# WKUP_CTRL_MMR0_CFG0 register map
Vendor: Texas Instruments
Registers are 32-bit, read-write, reset 0x0 unless marked. A register's access mark holds for its fields unless they carry their own. Offsets are as the file gives them; [hi:lo] are bit positions; {n}, {i} and the like mark numbered series; 'fields as' and 'values as' point back to an identical list.

## WKUP_CTRL_MMR0_CFG0 (part 3 of 11)
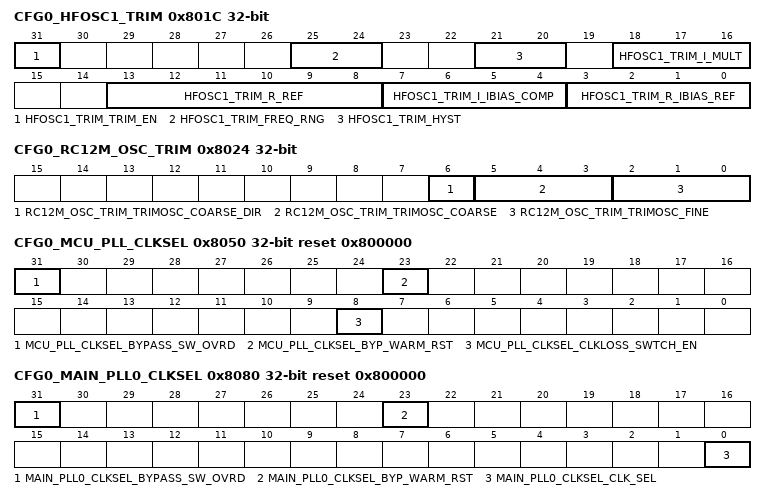
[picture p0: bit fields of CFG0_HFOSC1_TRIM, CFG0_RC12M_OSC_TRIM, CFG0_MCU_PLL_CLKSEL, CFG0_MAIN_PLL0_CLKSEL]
0x801C CFG0_HFOSC1_TRIM — Provides frequency trimming for oscillator 1
  [31] HFOSC1_TRIM_TRIM_EN — Apply MMR values to OSC trim inputs instead of tie-offs
  [25:24] HFOSC1_TRIM_FREQ_RNG — Sets the frequency range of operation based on:I(MIRRBIAS) = I(AGC) + 4x I(BIAS) (I(BIAS) : Bias current to AMP_AGC Block, I(AGC) : Current from AGC Loop and mirrored)
  [21:20] HFOSC1_TRIM_HYST — Sets comparator hysteresis
  [18:16] HFOSC1_TRIM_I_MULT — AGC AMP current multiplication gainI(MIRRBIAS) = I(AGC) + 4x I(BIAS) (I(BIAS) : Bias current to AMP_AGC Block, I(AGC) : Current from AGC Loop and mirrored)
  [13:8] HFOSC1_TRIM_R_REF — Sets the AMP AGC bias currentr_ref(5:3) are not used.
  [7:4] HFOSC1_TRIM_I_IBIAS_COMP — Sets the COMP bias currentx = 1 uA
  [3:0] HFOSC1_TRIM_R_IBIAS_REF — Sets the base IBIAS reference
0x8024 CFG0_RC12M_OSC_TRIM — Provides frequency trimming for the 12.5 MHz RC oscillator module
  [6] RC12M_OSC_TRIM_TRIMOSC_COARSE_DIR — Coarse adjustment direction. If output is greater than 12.5 0 - Coarse adjustment decreases frequency 1 - Coarse adjustment increases frequency
  [5:3] RC12M_OSC_TRIM_TRIMOSC_COARSE — Coarse adjustment. Frequency is decreased or increased by 1.25 MHz per value based on the trimosc_coarse_dir value.
  [2:0] RC12M_OSC_TRIM_TRIMOSC_FINE — Fine adjustment. Decreases the frequency by 250 KHz per value.
0x8050 CFG0_MCU_PLL_CLKSEL reset 0x800000 — Controls the clock source for MCU voltage domain PLL[2:0]
  [31] MCU_PLL_CLKSEL_BYPASS_SW_OVRD — PLL Bypass warm reset software overrideWhen set, enables software control of exit from bypass mode on a mcu_reset_z for MCU PLL[2:0]. This bit must not be set until after the corresponding byp_warm_rst bit has been cleared or the PLL will immediately enter bypass mode.
  [23] MCU_PLL_CLKSEL_BYP_WARM_RST — PLL bypass mode after warm reset.This bit is only valid when bypass_sw_ovrd is set to 1'b1 to enable bypass software override.This bit is set (1'b1) when an MCU warm reset occurs and will keep MCU PLL[2:0] in bypass mode after reset exit until cleared by software. 1'b0 = Exit bypass mode (based on MCU PLL[2:0]_CTRL_bypass_en bit value) 1'b1 = Maintain bypass mode.
  [8] MCU_PLL_CLKSEL_CLKLOSS_SWTCH_EN — When set, enables automatic switching of MCU PLL[2:0] clock source to CLK_12M_RC if HFOSC0 clock loss is detected
0x8060 CFG0_WKUP_PER_CLKSEL — Controls the wakeup peripheral functional clock source. Allows the main oscillator to be used as the functional clock source for the WKUP_USART and WKUP_I2C when PLLs are powered down.
  [0] WKUP_PER_CLKSEL_MCUPLL_BYPASS — Select the main oscillator clock rather than the PLL generated clock as the functional clock (PLL BYPASS mode). 1'b0:WKUP_I2C functional clock is MCU_PLL1_HSDIV3_CLKOUTWKUP_USART functional clock is MCU_PLL1_HSDIV3_CLKOUT or MAIN_PLL_HSDIV5_CLKOUT as selected by WKUP_USART_CLKSEL.clk_sel 1'b1:WKUP_I2C functional clock is HFOSC0_CLKOUTWKUP_USART functional clock is HFOSC0_CLKOUT
0x8064 CFG0_WKUP_USART_CLKSEL — Controls the functional clock source for WKUP_USART0
  [0] WKUP_USART_CLKSEL_CLK_SEL — WKUP_USART0 FCLK selection 1'b0 - MCU_PLL1_HSDIV3_CLKOUT 1'b1 - MAIN_PLL_HSDIV5_CLKOUT
0x8070 CFG0_WKUP_GPIO_CLKSEL — Controls the functional clock source for WKUP_GPIO
  [1:0] WKUP_GPIO_CLKSEL_WAKE_CLK_SEL — WKUP_GPIO clock selection. Must be set to MCU_SYSCLK0/4 whenever WKUP_GPIO VBUS interface is enabled. Other clock source may be selected as a wake up clock for DeepSleep modes after WKUP_GPIO is gated off through LPSC. Field values (Others are reserved): 2'b00 - MCU_SYSCLK0 / 8 2'b01 - MCU_SYSCLK0 / 8 2'b10 - CLK_32K 2'b11 - CLK_12M_RC
0x8080 CFG0_MAIN_PLL0_CLKSEL reset 0x800000 — Controls the clock source for MAIN voltage domain PLL0
  [31] MAIN_PLL0_CLKSEL_BYPASS_SW_OVRD — PLL Bypass warm reset software overrideWhen set, enables software control of exit from bypass mode on a main_reset_z for MAIN PLL0. This bit must not be set until after the corresponding byp_warm_rst bit has been cleared or the PLL will immediately enter bypass mode.
  [23] MAIN_PLL0_CLKSEL_BYP_WARM_RST — PLL bypass mode after warm reset.This bit is only valid when bypass_sw_ovrd is set to 1'b1 to enable bypass software override.This bit is set (1'b1) when a MAIN warm reset occurs and will keep MAIN PLL0 in bypass mode after reset exit until cleared by software. 1'b0 = Exit bypass mode (based on MAIN PLL0_CTRL_bypass_en bit value) 1'b1 = Maintain bypass mode.
  [0] MAIN_PLL0_CLKSEL_CLK_SEL — Selects the clock source for MAIN PLL0 1'b0 - Use HFOSC0_CLKOUT 1'b1 - Use HFOSC1_CLKOUT
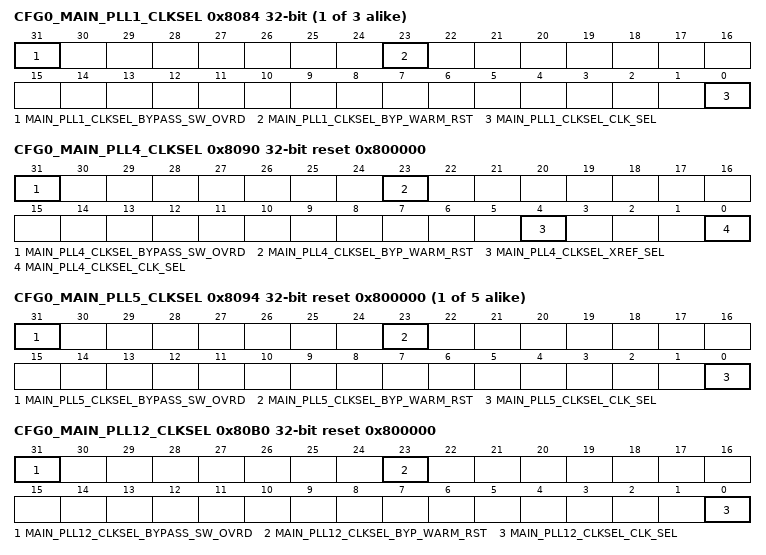
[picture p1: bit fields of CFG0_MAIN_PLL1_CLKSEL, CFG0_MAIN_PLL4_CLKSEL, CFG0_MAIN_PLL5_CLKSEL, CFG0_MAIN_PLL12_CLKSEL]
{0x8080+4i} CFG0_MAIN_PLL{i}_CLKSEL (i=1..3) — Controls the clock source for MAIN voltage domain PLL{i}
  [31] MAIN_PLL{i}_CLKSEL_BYPASS_SW_OVRD — PLL Bypass warm reset software overrideThis bit has no effect on PLL operation as MAIN PLL{i} is reset isolated and exit from bypass mode (in the case of a Thermal reset) is always hardware controlled.
  [23] MAIN_PLL{i}_CLKSEL_BYP_WARM_RST — PLL bypass mode after warm reset.This bit is cleared to 1'b0 when a MAIN warm reset occurs which will cause MAIN PLL{i} to exit bypass mode after reset exit. Setting this bit will have no effect on PLL behavior. Because MAIN PLL{i} is warm reset insensitive, bypass mode will only be entered (and exited) in the case of a Thermal reset event.
  [0] MAIN_PLL{i}_CLKSEL_CLK_SEL — Selects the clock source for MAIN PLL{i} 1'b0 - Use HFOSC0_CLKOUT 1'b1 - Use HFOSC1_CLKOUT
0x8090 CFG0_MAIN_PLL4_CLKSEL reset 0x800000 — Controls the clock source for MAIN voltage domain PLL4
  [31] MAIN_PLL4_CLKSEL_BYPASS_SW_OVRD — PLL Bypass warm reset software overrideWhen set, enables software control of exit from bypass mode on a main_reset_z for MAIN PLL4. This bit must not be set until after the corresponding byp_warm_rst bit has been cleared or the PLL will immediately enter bypass mode.
  [23] MAIN_PLL4_CLKSEL_BYP_WARM_RST — PLL bypass mode after warm reset.This bit is only valid when bypass_sw_ovrd is set to 1'b1 to enable bypass software override.This bit is set (1'b1) when a MAIN warm reset occurs and will keep MAIN PLL4 in bypass mode after reset exit until cleared by software. 1'b0 = Exit bypass mode (based on MAIN PLL4_CTRL_bypass_en bit value) 1'b1 = Maintain bypass mode.
  [4] MAIN_PLL4_CLKSEL_XREF_SEL — Selects the alternate clock source for MAIN PLL4 1'b0 - Use HFOSC0_CLKOUT or HFOSC1 CLKOUT as selected by clk_sel bit 1'b1 - Use EXT_REFCLK1
  [0] MAIN_PLL4_CLKSEL_CLK_SEL — Selects the clock source for MAIN PLL4 1'b0 - Use HFOSC0_CLKOUT 1'b1 - Use HFOSC1_CLKOUT
{0x8080+4i} CFG0_MAIN_PLL{i}_CLKSEL reset 0x800000 (i=5..9) — Controls the clock source for MAIN voltage domain PLL{i}
  [31] MAIN_PLL{i}_CLKSEL_BYPASS_SW_OVRD — PLL Bypass warm reset software overrideWhen set, enables software control of exit from bypass mode on a main_reset_z for MAIN PLL{i}. This bit must not be set until after the corresponding byp_warm_rst bit has been cleared or the PLL will immediately enter bypass mode.
  [23] MAIN_PLL{i}_CLKSEL_BYP_WARM_RST — PLL bypass mode after warm reset.This bit is only valid when bypass_sw_ovrd is set to 1'b1 to enable bypass software override.This bit is set (1'b1) when a MAIN warm reset occurs and will keep MAIN PLL{i} in bypass mode after reset exit until cleared by software. 1'b0 = Exit bypass mode (based on MAIN PLL{i}_CTRL_bypass_en bit value) 1'b1 = Maintain bypass mode.
  [0] MAIN_PLL{i}_CLKSEL_CLK_SEL — Selects the clock source for MAIN PLL{i} 1'b0 - Use HFOSC0_CLKOUT 1'b1 - Use HFOSC1_CLKOUT
0x80B0 CFG0_MAIN_PLL12_CLKSEL reset 0x800000 — Controls the clock source for MAIN voltage domain PLL12
  [31] MAIN_PLL12_CLKSEL_BYPASS_SW_OVRD — PLL Bypass warm reset software overrideWhen set, enables software control of exit from bypass mode on a main_reset_z for MAIN PLL12. This bit must not be set until after the corresponding byp_warm_rst bit has been cleared or the PLL will immediately enter bypass mode.
  [23] MAIN_PLL12_CLKSEL_BYP_WARM_RST — PLL bypass mode after warm reset.This bit is only valid when bypass_sw_ovrd is set to 1'b1 to enable bypass software override.This bit is set (1'b1) when a MAIN warm reset occurs and will keep MAIN PLL12 in bypass mode after reset exit until cleared by software. 1'b0 = Exit bypass mode (based on MAIN PLL12_CTRL_bypass_en bit value) 1'b1 = Maintain bypass mode.
  [0] MAIN_PLL12_CLKSEL_CLK_SEL — Selects the clock source for MAIN PLL12 1'b0 - Use HFOSC0_CLKOUT 1'b1 - Use HFOSC1_CLKOUT
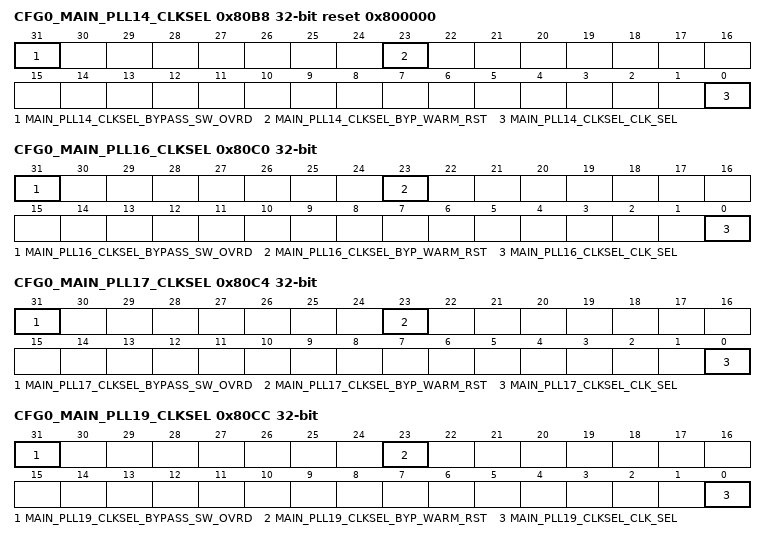
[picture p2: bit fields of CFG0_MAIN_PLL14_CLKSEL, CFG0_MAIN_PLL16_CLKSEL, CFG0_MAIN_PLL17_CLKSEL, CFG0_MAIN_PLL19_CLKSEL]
0x80B8 CFG0_MAIN_PLL14_CLKSEL reset 0x800000 — Controls the clock source for MAIN voltage domain PLL14
  [31] MAIN_PLL14_CLKSEL_BYPASS_SW_OVRD — PLL Bypass warm reset software overrideWhen set, enables software control of exit from bypass mode on a main_reset_z for MAIN PLL14. This bit must not be set until after the corresponding byp_warm_rst bit has been cleared or the PLL will immediately enter bypass mode.
  [23] MAIN_PLL14_CLKSEL_BYP_WARM_RST — PLL bypass mode after warm reset.This bit is only valid when bypass_sw_ovrd is set to 1'b1 to enable bypass software override.This bit is set (1'b1) when a MAIN warm reset occurs and will keep MAIN PLL14 in bypass mode after reset exit until cleared by software. 1'b0 = Exit bypass mode (based on MAIN PLL14_CTRL_bypass_en bit value) 1'b1 = Maintain bypass mode.
  [0] MAIN_PLL14_CLKSEL_CLK_SEL — Selects the clock source for MAIN PLL14 1'b0 - Use HFOSC0_CLKOUT 1'b1 - Use HFOSC1_CLKOUT
0x80C0 CFG0_MAIN_PLL16_CLKSEL — Controls the clock source for MAIN voltage domain PLL16
  [31] MAIN_PLL16_CLKSEL_BYPASS_SW_OVRD — PLL Bypass warm reset software overrideThis bit has no effect on PLL operation as MAIN PLL16 is reset isolated and exit from bypass mode (in the case of a Thermal reset) is always hardware controlled.
  [23] MAIN_PLL16_CLKSEL_BYP_WARM_RST — PLL bypass mode after warm reset.This bit is cleared to 1'b0 when a MAIN warm reset occurs which will cause MAIN PLL16 to exit bypass mode after reset exit. Setting this bit will have no effect on PLL behavior. Because MAIN PLL16 is warm reset insensitive, bypass mode will only be entered (and exited) in the case of a Thermal reset event.
  [0] MAIN_PLL16_CLKSEL_CLK_SEL — Selects the clock source for MAIN PLL16 1'b0 - Use HFOSC0_CLKOUT 1'b1 - Use HFOSC1_CLKOUT
0x80C4 CFG0_MAIN_PLL17_CLKSEL — Controls the clock source for MAIN voltage domain PLL17
  [31] MAIN_PLL17_CLKSEL_BYPASS_SW_OVRD — PLL Bypass warm reset software overrideThis bit has no effect on PLL operation as MAIN PLL17 is reset isolated and exit from bypass mode (in the case of a Thermal reset) is always hardware controlled.
  [23] MAIN_PLL17_CLKSEL_BYP_WARM_RST — PLL bypass mode after warm reset.This bit is cleared to 1'b0 when a MAIN warm reset occurs which will cause MAIN PLL17 to exit bypass mode after reset exit. Setting this bit will have no effect on PLL behavior. Because MAIN PLL17 is warm reset insensitive, bypass mode will only be entered (and exited) in the case of a Thermal reset event.
  [0] MAIN_PLL17_CLKSEL_CLK_SEL — Selects the clock source for MAIN PLL17 1'b0 - Use HFOSC0_CLKOUT 1'b1 - Use HFOSC1_CLKOUT
0x80CC CFG0_MAIN_PLL19_CLKSEL — Controls the clock source for MAIN voltage domain PLL19
  [31] MAIN_PLL19_CLKSEL_BYPASS_SW_OVRD — PLL Bypass warm reset software overrideThis bit has no effect on PLL operation as MAIN PLL19 is reset isolated and exit from bypass mode (in the case of a Thermal reset) is always hardware controlled.
  [23] MAIN_PLL19_CLKSEL_BYP_WARM_RST — PLL bypass mode after warm reset.This bit is cleared to 1'b0 when a MAIN warm reset occurs which will cause MAIN PLL19 to exit bypass mode after reset exit. Setting this bit will have no effect on PLL behavior. Because MAIN PLL19 is warm reset insensitive, bypass mode will only be entered (and exited) in the case of a Thermal reset event.
  [0] MAIN_PLL19_CLKSEL_CLK_SEL — Selects the clock source for MAIN PLL19 1'b0 - Use HFOSC0_CLKOUT 1'b1 - Use HFOSC1_CLKOUT
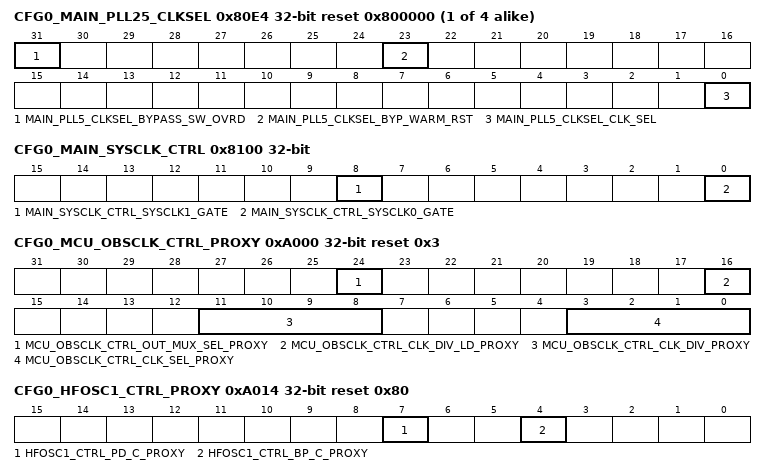
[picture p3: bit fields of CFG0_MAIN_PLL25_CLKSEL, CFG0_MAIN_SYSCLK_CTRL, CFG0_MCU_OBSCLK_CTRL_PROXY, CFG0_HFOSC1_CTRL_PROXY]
{0x8080+4i} CFG0_MAIN_PLL{i}_CLKSEL reset 0x800000 (i=25..28) — Controls the clock source for MAIN voltage domain PLL{i}
  fields as CFG0_MAIN_PLL5_CLKSEL
0x8100 CFG0_MAIN_SYSCLK_CTRL — Controls clock gating of the MAIN PLL Controller SYSCLK outputs
  [8] MAIN_SYSCLK_CTRL_SYSCLK1_GATE — When set, gates off SYSCLK1 output of the MAIN PLL Controller
  [0] MAIN_SYSCLK_CTRL_SYSCLK0_GATE — When set, gates off SYSCLK0 (MCLK1) output of the MAIN PLL Controller
0x8110 CFG0_MCU_SPI0_CLKSEL — MCU_SPI0 clock control
  [16] MCU_SPI0_CLKSEL_MSTR_LB_CLKSEL — Master mode receive capture clock loopback selection 1'b0 - Internal clock loopback 1'b1 - Loopback from pad
0x8114 CFG0_MCU_SPI1_CLKSEL — MCU_SPI1 clock control
  [16] MCU_SPI1_CLKSEL_MSTR_LB_CLKSEL — Master mode receive capture clock loopback selection 1'b0 - Internal clock loopback 1'b1 - Loopback from pad
{0x9100+4i} CFG0_CLAIMREG_P2_R{i}_READONLY ro (i=0..2)
  [31:0] CLAIMREG_P2_R{i}_READONLY — Claim bits for Partition 2
0xA000 CFG0_MCU_OBSCLK_CTRL_PROXY reset 0x3 — Controls which internal clock is made observable on the MCU_OBSCLK output pin
  [24] MCU_OBSCLK_CTRL_OUT_MUX_SEL_PROXY — MCU_OBSCLK pin output mux selection.Note, when HFOSC0_CLK is selected (1'b1) the MCU_OBSCLK_CTRL_clk_sel field must be programmed to 4'b0001. 1'b0 - The output of the MCU_OBSCLK output divider is output on the pin 1'b1 - HFOSC0_CLK is output on the pin
  [16] MCU_OBSCLK_CTRL_CLK_DIV_LD_PROXY — Load the output divider valueWriting 1 to this bit will generate a load pulse to load the OBSCLK divider value. This bit can be cleared but must not be set in the same write cycle in which the clk_div value is changed.
  [11:8] MCU_OBSCLK_CTRL_CLK_DIV_PROXY — MCU_OBSCLK pin clock selection output dividerOutput clock is divided by clk_div+1
  [3:0] MCU_OBSCLK_CTRL_CLK_SEL_PROXY — MCU_OBSCLK pin clock selection Field values (Others are reserved): 4'b0000 - CLK_12M_RC 4'b0001 - 0 4'b0010 - MCU_PLL0_HSDIV0_CLKOUT 4'b0011 - MCU_PLLCTL_OBSCLK 4'b0100 - MCU_PLL1_HSDIV1_CLKOUT 4'b0101 - MCU_PLL1_HSDIV2_CLKOUT 4'b0110 - MCU_PLL1_HSDIV3_CLKOUT 4'b0111 - MCU_PLL1_HSDIV4_CLKOUT 4'b1000 - MCU_PLL2_HSDIV0_CLKOUT 4'b1001 - CLK_32K 4'b1010 - MCU_PLL2_HSDIV1_CLKOUT 4'b1011 - MCU_PLL2_HSDIV2_CLKOUT 4'b1100 - MCU_PLL2_HSDIV3_CLKOUT 4'b1101 - MCU_PLL2_HSDIV4_CLKOUT 4'b1110 - HFOSC0_CLKOUT 4'b1111 - LFXOSC_CLKOUT
0xA014 CFG0_HFOSC1_CTRL_PROXY reset 0x80 — Controls the operation of oscillator 1
  [7] HFOSC1_CTRL_PD_C_PROXY — Oscillator powerdown control. When set, oscillator is disabled. Oscillator output is tristated if bp_c=0
  [4] HFOSC1_CTRL_BP_C_PROXY — Oscillator bypass control. When set oscillator is in bypass mode
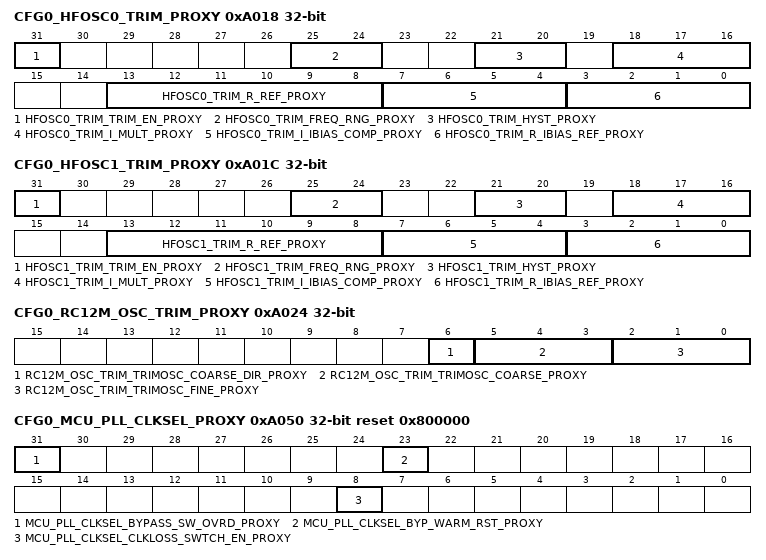
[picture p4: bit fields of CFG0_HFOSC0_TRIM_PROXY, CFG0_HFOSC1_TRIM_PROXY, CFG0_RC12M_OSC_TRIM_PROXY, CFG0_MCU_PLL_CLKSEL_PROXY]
0xA018 CFG0_HFOSC0_TRIM_PROXY — Provides frequency trimming for oscillator 0
  [31] HFOSC0_TRIM_TRIM_EN_PROXY — Apply MMR values to OSC trim inputs instead of tie-offs
  [25:24] HFOSC0_TRIM_FREQ_RNG_PROXY — Sets the frequency range of operation based on:I(MIRRBIAS) = I(AGC) + 4x I(BIAS) (I(BIAS) : Bias current to AMP_AGC Block, I(AGC) : Current from AGC Loop and mirrored)
  [21:20] HFOSC0_TRIM_HYST_PROXY — Sets comparator hysteresis
  [18:16] HFOSC0_TRIM_I_MULT_PROXY — AGC AMP current multiplication gainI(MIRRBIAS) = I(AGC) + 4x I(BIAS) (I(BIAS) : Bias current to AMP_AGC Block, I(AGC) : Current from AGC Loop and mirrored)
  [13:8] HFOSC0_TRIM_R_REF_PROXY — Sets the AMP AGC bias currentr_ref(5:3) are not used.
  [7:4] HFOSC0_TRIM_I_IBIAS_COMP_PROXY — Sets the COMP bias currentx = 1 uA
  [3:0] HFOSC0_TRIM_R_IBIAS_REF_PROXY — Sets the base IBIAS reference
0xA01C CFG0_HFOSC1_TRIM_PROXY — Provides frequency trimming for oscillator 1
  [31] HFOSC1_TRIM_TRIM_EN_PROXY — Apply MMR values to OSC trim inputs instead of tie-offs
  [25:24] HFOSC1_TRIM_FREQ_RNG_PROXY — Sets the frequency range of operation based on:I(MIRRBIAS) = I(AGC) + 4x I(BIAS) (I(BIAS) : Bias current to AMP_AGC Block, I(AGC) : Current from AGC Loop and mirrored)
  [21:20] HFOSC1_TRIM_HYST_PROXY — Sets comparator hysteresis
  [18:16] HFOSC1_TRIM_I_MULT_PROXY — AGC AMP current multiplication gainI(MIRRBIAS) = I(AGC) + 4x I(BIAS) (I(BIAS) : Bias current to AMP_AGC Block, I(AGC) : Current from AGC Loop and mirrored)
  [13:8] HFOSC1_TRIM_R_REF_PROXY — Sets the AMP AGC bias currentr_ref(5:3) are not used.
  [7:4] HFOSC1_TRIM_I_IBIAS_COMP_PROXY — Sets the COMP bias currentx = 1 uA
  [3:0] HFOSC1_TRIM_R_IBIAS_REF_PROXY — Sets the base IBIAS reference
0xA024 CFG0_RC12M_OSC_TRIM_PROXY — Provides frequency trimming for the 12.5 MHz RC oscillator module
  [6] RC12M_OSC_TRIM_TRIMOSC_COARSE_DIR_PROXY — Coarse adjustment direction. If output is greater than 12.5 0 - Coarse adjustment decreases frequency 1 - Coarse adjustment increases frequency
  [5:3] RC12M_OSC_TRIM_TRIMOSC_COARSE_PROXY — Coarse adjustment. Frequency is decreased or increased by 1.25 MHz per value based on the trimosc_coarse_dir value.
  [2:0] RC12M_OSC_TRIM_TRIMOSC_FINE_PROXY — Fine adjustment. Decreases the frequency by 250 KHz per value.
0xA050 CFG0_MCU_PLL_CLKSEL_PROXY reset 0x800000 — Controls the clock source for MCU voltage domain PLL[2:0]
  [31] MCU_PLL_CLKSEL_BYPASS_SW_OVRD_PROXY — PLL Bypass warm reset software overrideWhen set, enables software control of exit from bypass mode on a mcu_reset_z for MCU PLL[2:0]. This bit must not be set until after the corresponding byp_warm_rst bit has been cleared or the PLL will immediately enter bypass mode.
  [23] MCU_PLL_CLKSEL_BYP_WARM_RST_PROXY — PLL bypass mode after warm reset.This bit is only valid when bypass_sw_ovrd is set to 1'b1 to enable bypass software override.This bit is set (1'b1) when an MCU warm reset occurs and will keep MCU PLL[2:0] in bypass mode after reset exit until cleared by software. 1'b0 = Exit bypass mode (based on MCU PLL[2:0]_CTRL_bypass_en bit value) 1'b1 = Maintain bypass mode.
  [8] MCU_PLL_CLKSEL_CLKLOSS_SWTCH_EN_PROXY — When set, enables automatic switching of MCU PLL[2:0] clock source to CLK_12M_RC if HFOSC0 clock loss is detected
0xA060 CFG0_WKUP_PER_CLKSEL_PROXY — Controls the wakeup peripheral functional clock source. Allows the main oscillator to be used as the functional clock source for the WKUP_USART and WKUP_I2C when PLLs are powered down.
  [0] WKUP_PER_CLKSEL_MCUPLL_BYPASS_PROXY — Select the main oscillator clock rather than the PLL generated clock as the functional clock (PLL BYPASS mode). 1'b0:WKUP_I2C functional clock is MCU_PLL1_HSDIV3_CLKOUTWKUP_USART functional clock is MCU_PLL1_HSDIV3_CLKOUT or MAIN_PLL_HSDIV5_CLKOUT as selected by WKUP_USART_CLKSEL.clk_sel 1'b1:WKUP_I2C functional clock is HFOSC0_CLKOUTWKUP_USART functional clock is HFOSC0_CLKOUT
0xA064 CFG0_WKUP_USART_CLKSEL_PROXY — Controls the functional clock source for WKUP_USART0
  [0] WKUP_USART_CLKSEL_CLK_SEL_PROXY — WKUP_USART0 FCLK selection 1'b0 - MCU_PLL1_HSDIV3_CLKOUT 1'b1 - MAIN_PLL_HSDIV5_CLKOUT
0xA070 CFG0_WKUP_GPIO_CLKSEL_PROXY — Controls the functional clock source for WKUP_GPIO
  [1:0] WKUP_GPIO_CLKSEL_WAKE_CLK_SEL_PROXY — WKUP_GPIO clock selection. Must be set to MCU_SYSCLK0/4 whenever WKUP_GPIO VBUS interface is enabled. Other clock source may be selected as a wake up clock for DeepSleep modes after WKUP_GPIO is gated off through LPSC. Field values (Others are reserved): 2'b00 - MCU_SYSCLK0 / 8 2'b01 - MCU_SYSCLK0 / 8 2'b10 - CLK_32K 2'b11 - CLK_12M_RC
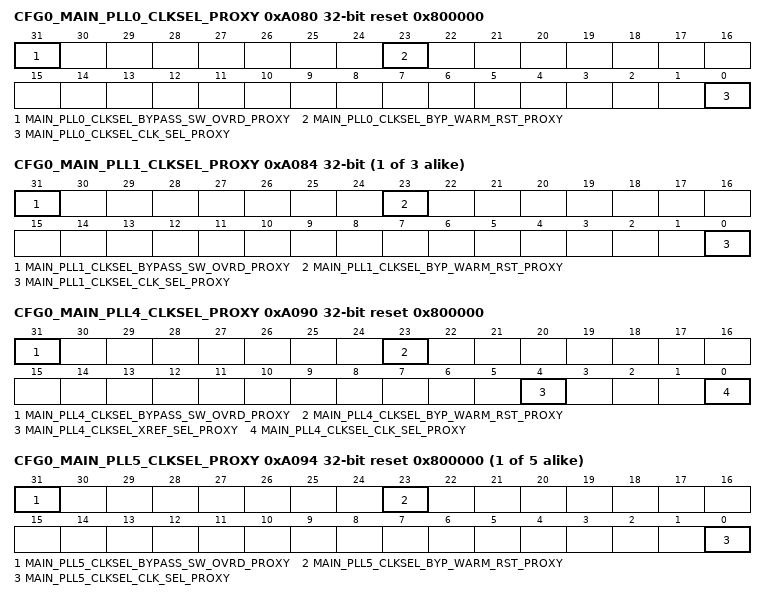
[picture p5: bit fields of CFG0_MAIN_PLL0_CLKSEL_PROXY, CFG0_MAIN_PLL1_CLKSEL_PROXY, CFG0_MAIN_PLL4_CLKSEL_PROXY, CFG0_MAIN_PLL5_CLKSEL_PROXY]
0xA080 CFG0_MAIN_PLL0_CLKSEL_PROXY reset 0x800000 — Controls the clock source for MAIN voltage domain PLL0
  [31] MAIN_PLL0_CLKSEL_BYPASS_SW_OVRD_PROXY — PLL Bypass warm reset software overrideWhen set, enables software control of exit from bypass mode on a main_reset_z for MAIN PLL0. This bit must not be set until after the corresponding byp_warm_rst bit has been cleared or the PLL will immediately enter bypass mode.
  [23] MAIN_PLL0_CLKSEL_BYP_WARM_RST_PROXY — PLL bypass mode after warm reset.This bit is only valid when bypass_sw_ovrd is set to 1'b1 to enable bypass software override.This bit is set (1'b1) when a MAIN warm reset occurs and will keep MAIN PLL0 in bypass mode after reset exit until cleared by software. 1'b0 = Exit bypass mode (based on MAIN PLL0_CTRL_bypass_en bit value) 1'b1 = Maintain bypass mode.
  [0] MAIN_PLL0_CLKSEL_CLK_SEL_PROXY — Selects the clock source for MAIN PLL0 1'b0 - Use HFOSC0_CLKOUT 1'b1 - Use HFOSC1_CLKOUT
{0xA080+4i} CFG0_MAIN_PLL{i}_CLKSEL_PROXY (i=1..3) — Controls the clock source for MAIN voltage domain PLL{i}
  [31] MAIN_PLL{i}_CLKSEL_BYPASS_SW_OVRD_PROXY — PLL Bypass warm reset software overrideThis bit has no effect on PLL operation as MAIN PLL{i} is reset isolated and exit from bypass mode (in the case of a Thermal reset) is always hardware controlled.
  [23] MAIN_PLL{i}_CLKSEL_BYP_WARM_RST_PROXY — PLL bypass mode after warm reset.This bit is cleared to 1'b0 when a MAIN warm reset occurs which will cause MAIN PLL{i} to exit bypass mode after reset exit. Setting this bit will have no effect on PLL behavior. Because MAIN PLL{i} is warm reset insensitive, bypass mode will only be entered (and exited) in the case of a Thermal reset event.
  [0] MAIN_PLL{i}_CLKSEL_CLK_SEL_PROXY — Selects the clock source for MAIN PLL{i} 1'b0 - Use HFOSC0_CLKOUT 1'b1 - Use HFOSC1_CLKOUT
0xA090 CFG0_MAIN_PLL4_CLKSEL_PROXY reset 0x800000 — Controls the clock source for MAIN voltage domain PLL4
  [31] MAIN_PLL4_CLKSEL_BYPASS_SW_OVRD_PROXY — PLL Bypass warm reset software overrideWhen set, enables software control of exit from bypass mode on a main_reset_z for MAIN PLL4. This bit must not be set until after the corresponding byp_warm_rst bit has been cleared or the PLL will immediately enter bypass mode.
  [23] MAIN_PLL4_CLKSEL_BYP_WARM_RST_PROXY — PLL bypass mode after warm reset.This bit is only valid when bypass_sw_ovrd is set to 1'b1 to enable bypass software override.This bit is set (1'b1) when a MAIN warm reset occurs and will keep MAIN PLL4 in bypass mode after reset exit until cleared by software. 1'b0 = Exit bypass mode (based on MAIN PLL4_CTRL_bypass_en bit value) 1'b1 = Maintain bypass mode.
  [4] MAIN_PLL4_CLKSEL_XREF_SEL_PROXY — Selects the alternate clock source for MAIN PLL4 1'b0 - Use HFOSC0_CLKOUT or HFOSC1 CLKOUT as selected by clk_sel bit 1'b1 - Use EXT_REFCLK1
  [0] MAIN_PLL4_CLKSEL_CLK_SEL_PROXY — Selects the clock source for MAIN PLL4 1'b0 - Use HFOSC0_CLKOUT 1'b1 - Use HFOSC1_CLKOUT
{0xA080+4i} CFG0_MAIN_PLL{i}_CLKSEL_PROXY reset 0x800000 (i=5..9) — Controls the clock source for MAIN voltage domain PLL{i}
  [31] MAIN_PLL{i}_CLKSEL_BYPASS_SW_OVRD_PROXY — PLL Bypass warm reset software overrideWhen set, enables software control of exit from bypass mode on a main_reset_z for MAIN PLL{i}. This bit must not be set until after the corresponding byp_warm_rst bit has been cleared or the PLL will immediately enter bypass mode.
  [23] MAIN_PLL{i}_CLKSEL_BYP_WARM_RST_PROXY — PLL bypass mode after warm reset.This bit is only valid when bypass_sw_ovrd is set to 1'b1 to enable bypass software override.This bit is set (1'b1) when a MAIN warm reset occurs and will keep MAIN PLL{i} in bypass mode after reset exit until cleared by software. 1'b0 = Exit bypass mode (based on MAIN PLL{i}_CTRL_bypass_en bit value) 1'b1 = Maintain bypass mode.
  [0] MAIN_PLL{i}_CLKSEL_CLK_SEL_PROXY — Selects the clock source for MAIN PLL{i} 1'b0 - Use HFOSC0_CLKOUT 1'b1 - Use HFOSC1_CLKOUT
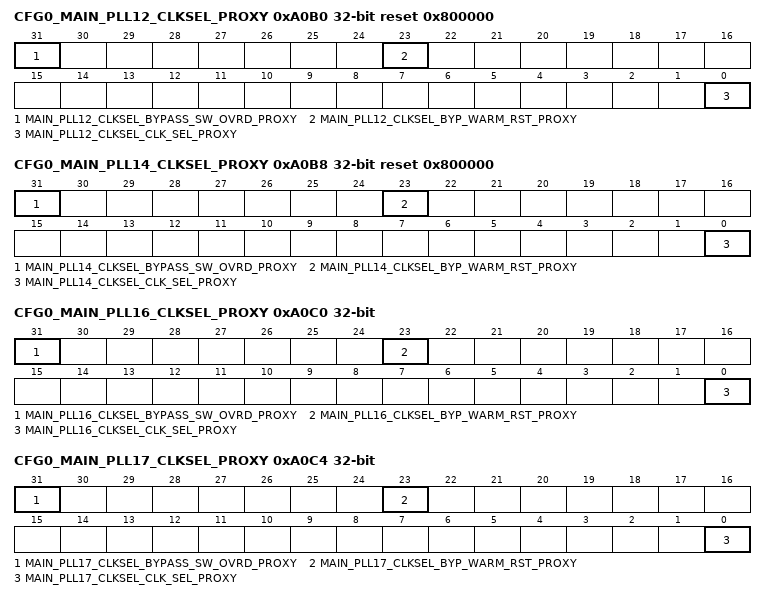
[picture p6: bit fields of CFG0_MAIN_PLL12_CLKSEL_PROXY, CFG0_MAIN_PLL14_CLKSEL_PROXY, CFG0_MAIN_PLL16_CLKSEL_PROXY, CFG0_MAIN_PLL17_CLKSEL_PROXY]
0xA0B0 CFG0_MAIN_PLL12_CLKSEL_PROXY reset 0x800000 — Controls the clock source for MAIN voltage domain PLL12
  [31] MAIN_PLL12_CLKSEL_BYPASS_SW_OVRD_PROXY — PLL Bypass warm reset software overrideWhen set, enables software control of exit from bypass mode on a main_reset_z for MAIN PLL12. This bit must not be set until after the corresponding byp_warm_rst bit has been cleared or the PLL will immediately enter bypass mode.
  [23] MAIN_PLL12_CLKSEL_BYP_WARM_RST_PROXY — PLL bypass mode after warm reset.This bit is only valid when bypass_sw_ovrd is set to 1'b1 to enable bypass software override.This bit is set (1'b1) when a MAIN warm reset occurs and will keep MAIN PLL12 in bypass mode after reset exit until cleared by software. 1'b0 = Exit bypass mode (based on MAIN PLL12_CTRL_bypass_en bit value) 1'b1 = Maintain bypass mode.
  [0] MAIN_PLL12_CLKSEL_CLK_SEL_PROXY — Selects the clock source for MAIN PLL12 1'b0 - Use HFOSC0_CLKOUT 1'b1 - Use HFOSC1_CLKOUT
0xA0B8 CFG0_MAIN_PLL14_CLKSEL_PROXY reset 0x800000 — Controls the clock source for MAIN voltage domain PLL14
  [31] MAIN_PLL14_CLKSEL_BYPASS_SW_OVRD_PROXY — PLL Bypass warm reset software overrideWhen set, enables software control of exit from bypass mode on a main_reset_z for MAIN PLL14. This bit must not be set until after the corresponding byp_warm_rst bit has been cleared or the PLL will immediately enter bypass mode.
  [23] MAIN_PLL14_CLKSEL_BYP_WARM_RST_PROXY — PLL bypass mode after warm reset.This bit is only valid when bypass_sw_ovrd is set to 1'b1 to enable bypass software override.This bit is set (1'b1) when a MAIN warm reset occurs and will keep MAIN PLL14 in bypass mode after reset exit until cleared by software. 1'b0 = Exit bypass mode (based on MAIN PLL14_CTRL_bypass_en bit value) 1'b1 = Maintain bypass mode.
  [0] MAIN_PLL14_CLKSEL_CLK_SEL_PROXY — Selects the clock source for MAIN PLL14 1'b0 - Use HFOSC0_CLKOUT 1'b1 - Use HFOSC1_CLKOUT
0xA0C0 CFG0_MAIN_PLL16_CLKSEL_PROXY — Controls the clock source for MAIN voltage domain PLL16
  [31] MAIN_PLL16_CLKSEL_BYPASS_SW_OVRD_PROXY — PLL Bypass warm reset software overrideThis bit has no effect on PLL operation as MAIN PLL16 is reset isolated and exit from bypass mode (in the case of a Thermal reset) is always hardware controlled.
  [23] MAIN_PLL16_CLKSEL_BYP_WARM_RST_PROXY — PLL bypass mode after warm reset.This bit is cleared to 1'b0 when a MAIN warm reset occurs which will cause MAIN PLL16 to exit bypass mode after reset exit. Setting this bit will have no effect on PLL behavior. Because MAIN PLL16 is warm reset insensitive, bypass mode will only be entered (and exited) in the case of a Thermal reset event.
  [0] MAIN_PLL16_CLKSEL_CLK_SEL_PROXY — Selects the clock source for MAIN PLL16 1'b0 - Use HFOSC0_CLKOUT 1'b1 - Use HFOSC1_CLKOUT
0xA0C4 CFG0_MAIN_PLL17_CLKSEL_PROXY — Controls the clock source for MAIN voltage domain PLL17
  [31] MAIN_PLL17_CLKSEL_BYPASS_SW_OVRD_PROXY — PLL Bypass warm reset software overrideThis bit has no effect on PLL operation as MAIN PLL17 is reset isolated and exit from bypass mode (in the case of a Thermal reset) is always hardware controlled.
  [23] MAIN_PLL17_CLKSEL_BYP_WARM_RST_PROXY — PLL bypass mode after warm reset.This bit is cleared to 1'b0 when a MAIN warm reset occurs which will cause MAIN PLL17 to exit bypass mode after reset exit. Setting this bit will have no effect on PLL behavior. Because MAIN PLL17 is warm reset insensitive, bypass mode will only be entered (and exited) in the case of a Thermal reset event.
  [0] MAIN_PLL17_CLKSEL_CLK_SEL_PROXY — Selects the clock source for MAIN PLL17 1'b0 - Use HFOSC0_CLKOUT 1'b1 - Use HFOSC1_CLKOUT
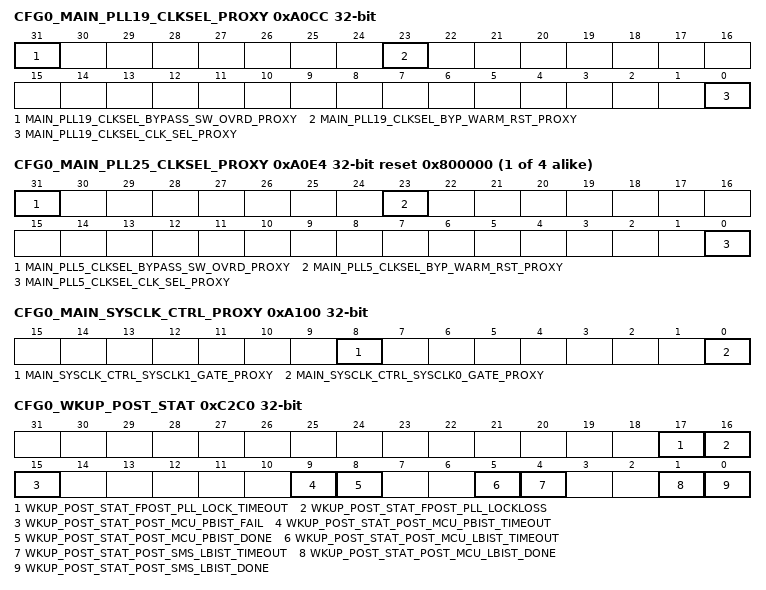
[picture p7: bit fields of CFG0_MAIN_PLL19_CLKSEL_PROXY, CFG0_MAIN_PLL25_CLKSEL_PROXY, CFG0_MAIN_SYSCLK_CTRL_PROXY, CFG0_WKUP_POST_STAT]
0xA0CC CFG0_MAIN_PLL19_CLKSEL_PROXY — Controls the clock source for MAIN voltage domain PLL19
  [31] MAIN_PLL19_CLKSEL_BYPASS_SW_OVRD_PROXY — PLL Bypass warm reset software overrideThis bit has no effect on PLL operation as MAIN PLL19 is reset isolated and exit from bypass mode (in the case of a Thermal reset) is always hardware controlled.
  [23] MAIN_PLL19_CLKSEL_BYP_WARM_RST_PROXY — PLL bypass mode after warm reset.This bit is cleared to 1'b0 when a MAIN warm reset occurs which will cause MAIN PLL19 to exit bypass mode after reset exit. Setting this bit will have no effect on PLL behavior. Because MAIN PLL19 is warm reset insensitive, bypass mode will only be entered (and exited) in the case of a Thermal reset event.
  [0] MAIN_PLL19_CLKSEL_CLK_SEL_PROXY — Selects the clock source for MAIN PLL19 1'b0 - Use HFOSC0_CLKOUT 1'b1 - Use HFOSC1_CLKOUT
{0xA080+4i} CFG0_MAIN_PLL{i}_CLKSEL_PROXY reset 0x800000 (i=25..28) — Controls the clock source for MAIN voltage domain PLL{i}
  fields as CFG0_MAIN_PLL5_CLKSEL_PROXY
0xA100 CFG0_MAIN_SYSCLK_CTRL_PROXY — Controls clock gating of the MAIN PLL Controller SYSCLK outputs
  [8] MAIN_SYSCLK_CTRL_SYSCLK1_GATE_PROXY — When set, gates off SYSCLK1 output of the MAIN PLL Controller
  [0] MAIN_SYSCLK_CTRL_SYSCLK0_GATE_PROXY — When set, gates off SYSCLK0 (MCLK1) output of the MAIN PLL Controller
0xA110 CFG0_MCU_SPI0_CLKSEL_PROXY — MCU_SPI0 clock control
  [16] MCU_SPI0_CLKSEL_MSTR_LB_CLKSEL_PROXY — Master mode receive capture clock loopback selection 1'b0 - Internal clock loopback 1'b1 - Loopback from pad
0xA114 CFG0_MCU_SPI1_CLKSEL_PROXY — MCU_SPI1 clock control
  [16] MCU_SPI1_CLKSEL_MSTR_LB_CLKSEL_PROXY — Master mode receive capture clock loopback selection 1'b0 - Internal clock loopback 1'b1 - Loopback from pad
{0xB100+4i} CFG0_CLAIMREG_P2_R{i} (i=0..2)
  [31:0] CLAIMREG_P2_R{i} — Claim bits for Partition 2
0xC280 CFG0_SMS_LBIST_SIG ro — Contains expected MISR output value
  [31:0] SMS_LBIST_SIG_MISR_SIG — MISR signature
0xC2C0 CFG0_WKUP_POST_STAT ro — Contains the result of power-on self tests.
  [17] WKUP_POST_STAT_FPOST_PLL_LOCK_TIMEOUT — Indicates PLL lock timeout for Fast POST mode operation. 0 - PLLs locked, Fast POST mode was entered 1 - PLLs lock timeout occurred. Slow speed POST was performed
  [16] WKUP_POST_STAT_FPOST_PLL_LOCKLOSS — Indicates if PLL lock was lost during POST 0 - No PLL lock loss. Fast POST was executed 1 - PLL lock was lost. POST was terminated
  [15] WKUP_POST_STAT_POST_MCU_PBIST_FAIL — MCU PBIST failed
  [9] WKUP_POST_STAT_POST_MCU_PBIST_TIMEOUT — MCU PBIST timed out
  [8] WKUP_POST_STAT_POST_MCU_PBIST_DONE — MCU PBIST done
  [5] WKUP_POST_STAT_POST_MCU_LBIST_TIMEOUT — MCU LBIST timed out
  [4] WKUP_POST_STAT_POST_SMS_LBIST_TIMEOUT — SMS LBIST timed out
  [1] WKUP_POST_STAT_POST_MCU_LBIST_DONE — MCU LBIST done
  [0] WKUP_POST_STAT_POST_SMS_LBIST_DONE — SMS LBIST done
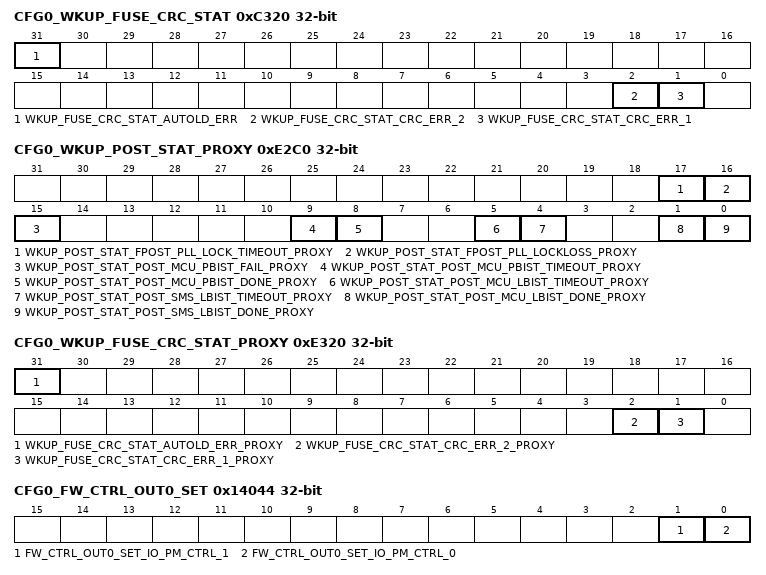
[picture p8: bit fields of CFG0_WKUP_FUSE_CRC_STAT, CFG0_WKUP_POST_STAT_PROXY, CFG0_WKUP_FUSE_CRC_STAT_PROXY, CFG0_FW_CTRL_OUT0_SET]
0xC320 CFG0_WKUP_FUSE_CRC_STAT ro — Indicates status of fuse chain CRC
  [31] WKUP_FUSE_CRC_STAT_AUTOLD_ERR — Indicates eFuse autoload or programmation error on any chain
  [2] WKUP_FUSE_CRC_STAT_CRC_ERR_2 — Indicates eFuse CRC error on chain 2
  [1] WKUP_FUSE_CRC_STAT_CRC_ERR_1 — Indicates eFuse CRC error on chain 1
{0xD100+4i} CFG0_CLAIMREG_P3_R{i}_READONLY ro (i=0..6)
  [31:0] CLAIMREG_P3_R{i}_READONLY — Claim bits for Partition 3
0xE280 CFG0_SMS_LBIST_SIG_PROXY ro — Contains expected MISR output value
  [31:0] SMS_LBIST_SIG_MISR_SIG_PROXY — MISR signature
0xE2C0 CFG0_WKUP_POST_STAT_PROXY ro — Contains the result of power-on self tests.
  [17] WKUP_POST_STAT_FPOST_PLL_LOCK_TIMEOUT_PROXY — Indicates PLL lock timeout for Fast POST mode operation. 0 - PLLs locked, Fast POST mode was entered 1 - PLLs lock timeout occurred. Slow speed POST was performed
  [16] WKUP_POST_STAT_FPOST_PLL_LOCKLOSS_PROXY — Indicates if PLL lock was lost during POST 0 - No PLL lock loss. Fast POST was executed 1 - PLL lock was lost. POST was terminated
  [15] WKUP_POST_STAT_POST_MCU_PBIST_FAIL_PROXY — MCU PBIST failed
  [9] WKUP_POST_STAT_POST_MCU_PBIST_TIMEOUT_PROXY — MCU PBIST timed out
  [8] WKUP_POST_STAT_POST_MCU_PBIST_DONE_PROXY — MCU PBIST done
  [5] WKUP_POST_STAT_POST_MCU_LBIST_TIMEOUT_PROXY — MCU LBIST timed out
  [4] WKUP_POST_STAT_POST_SMS_LBIST_TIMEOUT_PROXY — SMS LBIST timed out
  [1] WKUP_POST_STAT_POST_MCU_LBIST_DONE_PROXY — MCU LBIST done
  [0] WKUP_POST_STAT_POST_SMS_LBIST_DONE_PROXY — SMS LBIST done
0xE320 CFG0_WKUP_FUSE_CRC_STAT_PROXY ro — Indicates status of fuse chain CRC
  [31] WKUP_FUSE_CRC_STAT_AUTOLD_ERR_PROXY — Indicates eFuse autoload or programmation error on any chain
  [2] WKUP_FUSE_CRC_STAT_CRC_ERR_2_PROXY — Indicates eFuse CRC error on chain 2
  [1] WKUP_FUSE_CRC_STAT_CRC_ERR_1_PROXY — Indicates eFuse CRC error on chain 1
{0xF100+4i} CFG0_CLAIMREG_P3_R{i} (i=0..6)
  [31:0] CLAIMREG_P3_R{i} — Claim bits for Partition 3
{0x11100+4i} CFG0_CLAIMREG_P4_R{i}_READONLY ro (i=0..15)
  [31:0] CLAIMREG_P4_R{i}_READONLY — Claim bits for Partition 4
{0x13100+4i} CFG0_CLAIMREG_P4_R{i} (i=0..15)
  [31:0] CLAIMREG_P4_R{i} — Claim bits for Partition 4
0x14040 CFG0_FW_CTRL_OUT0 ro — This register is writable only when LOCK0-KICK0:1 are unlocked
  [1:0] FW_CTRL_OUT0_IO_PM_CTRL — This value is used by DMSC/SMS firmware to apply the DS (deep/deeper-sleep) values at once by qualifying the generation of the integration signal to the dsen_qualified to the IOs. These 2 bits are used in conjunction with those in the PMCTRL_IO_1/0 MMRs.The values gated/applied by dsen_qualified are those defined on the PADCONFIG MMR for each IO pad, as the DS selections, for the following IO pins:pupdsel, pi, txout, gz 0 - The active/normal mode pad-config defined values are applied to each IO/IO-pad that is part of the IO-PM daisy chain. 1 - The DS value, defined in the pad-config is applied to each IO/IO-pad that is part of the IO-PM daisy chain The io_pm_ctrl0 Is used to control deep/deeper-sleep values for the IOs in the WKUP section of the SOC. The io_pm_ctrl1 Is used to control deep/deeper-sleep values for the IOs in the MAIN section of the SOC.
0x14044 CFG0_FW_CTRL_OUT0_SET access not given — This register is writable only when LOCK0-KICK0:1 are unlocked
  [1] FW_CTRL_OUT0_SET_IO_PM_CTRL_1 — This MMR bit is a W1ts bit field for MMR-bit-field FW_CTRL_OUT0.io_pm_ctrl1 (access R/W1TS)
  [0] FW_CTRL_OUT0_SET_IO_PM_CTRL_0 — This MMR bit is a W1ts bit field for MMR-bit-field FW_CTRL_OUT0.io_pm_ctrl0 (access R/W1TS)
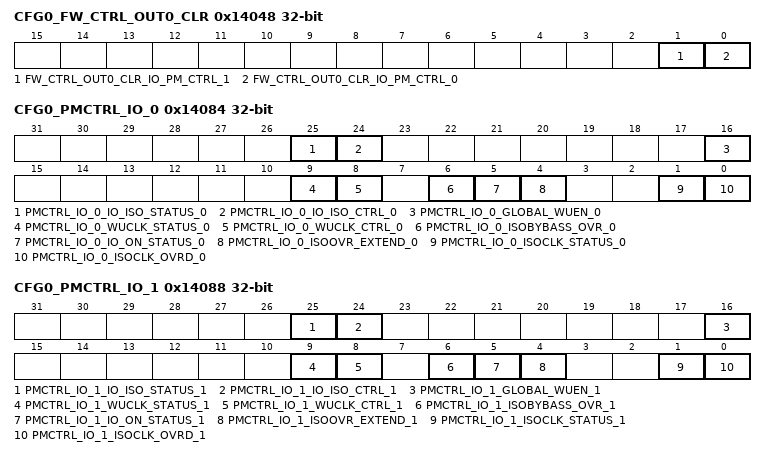
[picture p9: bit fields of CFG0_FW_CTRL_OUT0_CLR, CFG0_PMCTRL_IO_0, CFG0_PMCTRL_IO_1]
0x14048 CFG0_FW_CTRL_OUT0_CLR access not given — This register is writable only when LOCK0-KICK0:1 are unlocked
  [1] FW_CTRL_OUT0_CLR_IO_PM_CTRL_1 — This MMR bit is a W1ts bit field for MMR-bit-field FW_CTRL_OUT0.io_pm_ctrl1 (access R/W1TC)
  [0] FW_CTRL_OUT0_CLR_IO_PM_CTRL_0 — This MMR bit is a W1ts bit field for MMR-bit-field FW_CTRL_OUT0.io_pm_ctrl0 (access R/W1TC)
0x14080 CFG0_PMCTRL_SYS reset 0x10 — This register is writable only when LOCK0-KICK0:1 are unlocked. Notice that this MMR includes a write-enable bit per field
  [4] PMCTRL_SYS_PMIC_EN — PMIC enable. In order to write to this field, you need to write 1 in the same access to field pmic_en_we. NOTE: This MMR bit does not reflect any contribution from any debug related signal. 0 - Drives PMIC_EN output port to 0, unless there is an POWER-OFF inhibit condition due to Debug/Security 1 - Drives PMIC_EN output port to 1, if not already 1
0x14084 CFG0_PMCTRL_IO_0 access per field — Associated to the IO daisy chain of the safety_island IOs
  [25] PMCTRL_IO_0_IO_ISO_STATUS_0 ro — IO ISO Status 0 - IO isolation not active 1 - IO isolation active.Reflects value of SMS input port io_isoack coming back from IO pad ring
  [24] PMCTRL_IO_0_IO_ISO_CTRL_0 rw — IO ISO control. 0 - Turn off the IO isolation 1 - Turn on the IO isolation
  [16] PMCTRL_IO_0_GLOBAL_WUEN_0 rw — Global IO wakeup enable. This is a gating condition to all individual IO WUEN coming from control module. Gating is done in the Spinner logic. 0 - All individual IO WUEN are gated in the Spinner logic (override to 0). 1 - All individual IO WUEN from control module are going to IOs.Maps to SMS output port io_globalwkupen0 .
  [9] PMCTRL_IO_0_WUCLK_STATUS_0 ro — Reflects value of SMS input port io_wuclkack coming back from IO pad ring
  [8] PMCTRL_IO_0_WUCLK_CTRL_0 rw — Direct control on WUCLKIN signal to IO pad ring. 0 - WUCLKIN signal is driven to 0. IO wakeup daisy chain is functional as well as IO whose wakeup feature is enabled. 1 - WUCLKIN signal is driven to 1. IO wakeup daisy chain is reset and is latching current pad states and WUEN inputs
  [6] PMCTRL_IO_0_ISOBYBASS_OVR_0 rw — This MMR bit drives directly SMS output port io_isobypass0.
  [5] PMCTRL_IO_0_IO_ON_STATUS_0 ro — Gives the functional status of the IO ring. 0 - Part or all of the IOs are not in the ON state that is are in isolation state. 1 - All IOs are in the ON state. io_on_status = assign 1 if (io_iso == 0 & io_isoack==0 & io_iso_clk == 0 & io_isoclk_ack = 0 ) else 0;
  [4] PMCTRL_IO_0_ISOOVR_EXTEND_0 rw — Control for IO isolation extensionThis drives the SOC chain ISO-OVERRIDE global control.This bit drives directly the SMS output port io_isoovr0. At the SOC level it is used to enable when 1 or gate-off when 0, the individual ISOOR for each IO. This operates as a global enable/disable for the individual IOs. 0 - IO isolation is not extended. Transition happens as soon as automatic restore is completed. 1 - IO isolation is extended. The IOs whose ISOOVR bits have been individually set in their PADCFG MMRs will all get its IO isolation extended beyond the point when the initial IO daisy chain isolation is released.
  [1] PMCTRL_IO_0_ISOCLK_STATUS_0 ro — Reflects value of io_isoclkack coming back from IO pad ring.
  [0] PMCTRL_IO_0_ISOCLK_OVRD_0 rw — Override control on ISOCLKIN signal to IO pad ring.When not overridden this signal is controlled by hardware only. 0 - ISOCLKIN signal is not overriden. 1 - ISOCLKIN signal is overridden to active value (1).
0x14088 CFG0_PMCTRL_IO_1 access per field — MMR is associated to the IO daisy chain of the IOs in the VD_CORE domain (main-SOC).
  [25] PMCTRL_IO_1_IO_ISO_STATUS_1 ro — IO ISO Status 0 - IO isolation not active 1 - IO isolation active.Reflects value of SMS input port io_isoack coming back from IO pad ring
  [24] PMCTRL_IO_1_IO_ISO_CTRL_1 rw — IO ISO control. 0 - Turn off the IO isolation 1 - Turn on the IO isolation
  [16] PMCTRL_IO_1_GLOBAL_WUEN_1 rw — Global IO wakeup enable. This is a gating condition to all individual IO WUEN coming from control module. Gating is done in the Spinner logic. 0 - All individual IO WUEN are gated in the Spinner logic (override to 0). 1 - All individual IO WUEN from control module are going to IOs.Maps to SMS output port io_globalwkupen1 .
  [9] PMCTRL_IO_1_WUCLK_STATUS_1 ro — Reflects value of SMS input port io_wuclkack coming back from IO pad ring
  [8] PMCTRL_IO_1_WUCLK_CTRL_1 rw — Direct control on WUCLKIN signal to IO pad ring. 0 - WUCLKIN signal is driven to 0. IO wakeup daisy chain is functional as well as IO whose wakeup feature is enabled. 1 - WUCLKIN signal is driven to 1. IO wakeup daisy chain is reset and is latching current pad states and WUEN inputs
  [6] PMCTRL_IO_1_ISOBYBASS_OVR_1 rw — This MMR bit drives directly SMS output port io_isobypass[0].
  [5] PMCTRL_IO_1_IO_ON_STATUS_1 ro — Gives the functional status of the IO ring. 0 - Part or all of the IOs are not in the ON state that is are in isolation state. 1 - All IOs are in the ON state. io_on_status = assign 1 if (io_iso == 0 & io_isoack==0 & io_iso_clk == 0 & io_isoclk_ack = 0 ) else 0;
  [4] PMCTRL_IO_1_ISOOVR_EXTEND_1 rw — Control for IO isolation extensionThis drives the SOC chain ISO-OVERRIDE global control.This bit drives directly the SMS output port io_isoovr[0]. At the SOC level it is used to enable when 1 or gate-off when 0, the individual ISOOR for each IO. This operates as a global enable/disable for the individual IOs. 0 - IO isolation is not extended. Transition happens as soon as automatic restore is completed. 1 - IO isolation is extended. The IOs whose ISOOVR bits have been individually set in their PADCFG MMRs will all get its IO isolation extended beyond the point when the initial IO daisy chain isolation is released.
  [1] PMCTRL_IO_1_ISOCLK_STATUS_1 ro — Reflects value of io_isoclkack coming back from IO pad ring.
  [0] PMCTRL_IO_1_ISOCLK_OVRD_1 rw — Override control on ISOCLKIN signal to IO pad ring.When not overridden this signal is controlled by hardware only. 0 - ISOCLKIN signal is not overriden. 1 - ISOCLKIN signal is overridden to active value (1).
